# EFM32GG12B810F1024IL112 register map
File version: 3.0.0
CPU: CM4 r0p1, little endian, MPU, FPU, 3 interrupt priority bits
Registers are 32-bit, read-write, reset 0x0 unless marked. A register's access mark holds for its fields unless they carry their own. Offsets are from the block's base; [hi:lo] are bit positions; {n}, {i} and the like mark numbered series; 'fields as' and 'values as' point back to an identical list.

## CAN0
Base 0x40004000
Same registers: CAN1 0x40004400
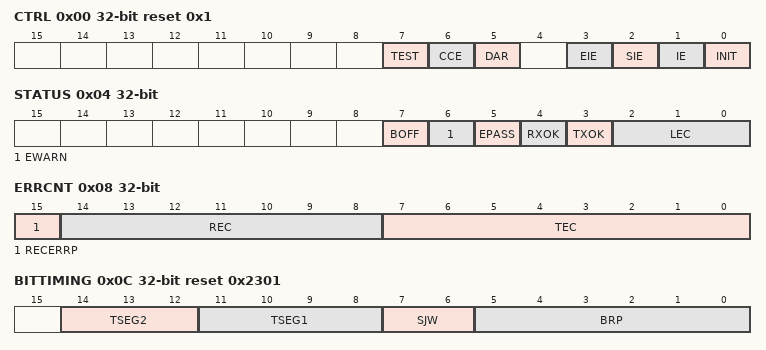
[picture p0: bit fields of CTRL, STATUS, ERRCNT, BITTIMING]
0x00 CTRL reset 0x1 — Control Register
  [7] TEST — Test Mode Enable Write
  [6] CCE — Configuration Change Enable
  [5] DAR — Disable Automatic Retransmission
  [3] EIE — Error Interrupt Enable
  [2] SIE — Status Change Interrupt Enable
  [1] IE — Module Interrupt Enable
  [0] INIT — Initialize
0x04 STATUS
  [7] BOFF ro — Bus Off Status
  [6] EWARN ro — Warning Status
  [5] EPASS ro — Error Passive
  [4] RXOK — Received a Message Successfully
  [3] TXOK — Transmitted a Message Successfully
  [2:0] LEC — Last Error Code
    0=NONE (No error occurred during last CAN bus event.); 1=STUFF (More than 5 equal bits in a sequence have occurred in a part of a received message where this is not allowed.); 2=FORM (A fixed format part of a received frame has the wrong format.); 3=ACK (The message this CAN Core transmitted was not acknowledged by another node.); 4=BIT1 (During the transmission of a message (with the exception of the arbitration field), the device wanted to send a recessive level (bit of logical value 1), but the monitored bus value was dominant.); 5=BIT0 (During the transmission of a message (or acknowledge bit, or active error flag, or overload flag), the device wanted to send a dominant level (data or identifier bit logical value 0), but the monitored Bus value was recessive. During Bus Off recovery this status is set each time a sequence of 11 recessive bits has been monitored. This enables the CPU to monitor the proceeding of the Bus Off recovery sequence (indicating the bus is not stuck at dominant or continuously disturbed).); 6=CRC (The CRC check sum was incorrect in the message received; the CRC received for an incoming message does not match with the calculated CRC for the received data.); 7=UNUSED (When the LEC shows the value '7', no CAN bus event was detected since the CPU wrote this value to the LEC.)
0x08 ERRCNT ro — Error Count Register
  [15] RECERRP — Receive Error Passive
  [14:8] REC — Receive Error Counter
  [7:0] TEC — Transmit Error Counter
0x0C BITTIMING reset 0x2301
  [14:12] TSEG2 — Time Segment After the Sample Point
  [11:8] TSEG1 — Time Segment Before the Sample Point
  [7:6] SJW — Synchronization Jump Width
  [5:0] BRP — Baud Rate Prescaler
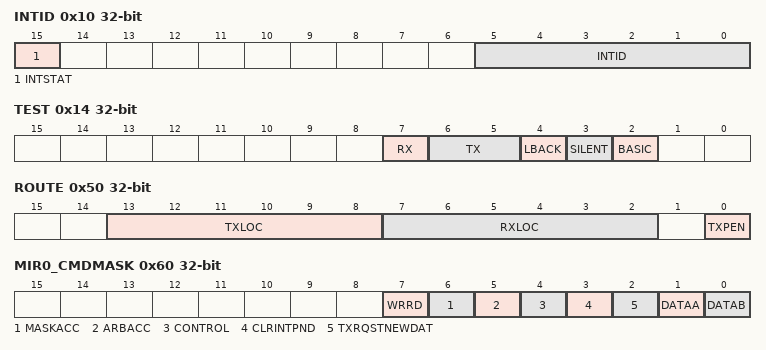
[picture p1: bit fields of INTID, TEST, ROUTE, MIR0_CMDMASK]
0x10 INTID ro — Interrupt Identification Register
  [15] INTSTAT — Status Interupt
  [5:0] INTID — Interrupt Identifier
0x14 TEST
  [7] RX ro — Monitors the Actual Value of CAN_RX Pin
  [6:5] TX — Control of CAN_TX Pin
    0=CORE (Reset value, CAN_TX is controlled by the CAN Core.); 1=SAMPT (Sample Point can be monitored at CAN_TX pin.); 2=LOW (CAN_TX pin drives a dominant bit (0) value.); 3=HIGH (CAN_TX pin drives a recessive bit (1) value.)
  [4] LBACK — Loopback Mode
  [3] SILENT — Silent Mode
  [2] BASIC — Basic Mode
0x18 BRPE — BRP Extension Register
  [3:0] BRPE — Baud Rate Prescaler Extension
0x1C TRANSREQ ro — Transmission Request Register
  [31:0] TXRQSTOUT — Transmission Request Bits (Of All Message Objects)
    0=FALSE (This Message Object is not waiting for transmission.); 1=TRUE (The transmission of this Message Object is requested and is not yet done.)
0x20 MESSAGEDATA ro — New Data Register
  [31:0] VALID — DATAVALID Bits (of All Message Objects)
0x28 MESSAGESTATE ro — Message Valid Register
  [31:0] VALID — Message Valid Bits (of All Message Objects)
0x2C CONFIG — Configuration Register
  [15] DBGHALT — Debug Halt
0x30 IF0IF ro — Message Object Interrupt Flag Register
  [31:0] MESSAGE — Message Object Interrupt Flag
0x34 IF0IFS wo — Message Object Interrupt Flag Set Register
  [31:0] MESSAGE — Set MESSAGE Interrupt Flag
0x38 IF0IFC wo — Message Object Interrupt Flag Clear Register
  [31:0] MESSAGE — Clear MESSAGE Interrupt Flag
0x3C IF0IEN reset 0xFFFFFFFF — Message Object Interrupt Enable Register
  [31:0] MESSAGE — MESSAGE Interrupt Enable
0x40 IF1IF ro — Status Interrupt Flag Register
  [0] STATUS — Status Interrupt Flag
0x44 IF1IFS wo — Message Object Interrupt Flag Set Register
  [0] STATUS — Set STATUS Interrupt Flag
0x48 IF1IFC wo — Message Object Interrupt Flag Clear Register
  [0] STATUS — Clear STATUS Interrupt Flag
0x4C IF1IEN reset 0x1 — Status Interrupt Enable Register
  [0] STATUS — STATUS Interrupt Enable
0x50 ROUTE — I/O Routing Register
  [13:8] TXLOC — TX Pin Location
    {v}=LOC{v} (Location {v}) (v=0..6)
  [7:2] RXLOC — RX Pin Location
    {v}=LOC{v} (Location {v}) (v=0..6)
  [0] TXPEN — TX Pin Enable
0x60 MIR0_CMDMASK — Interface Command Mask Register
  [7] WRRD — Write/Read RAM
  [6] MASKACC — Access Mask Bits
  [5] ARBACC — Access Arbitration Bits
  [4] CONTROL — Access Control Bits
  [3] CLRINTPND — Clear Interrupt Pending Bit
  [2] TXRQSTNEWDAT — Transmission Request Bit/ New Data Bit
  [1] DATAA — Access Data Bytes 0-3
  [0] DATAB — CC Channel Mode
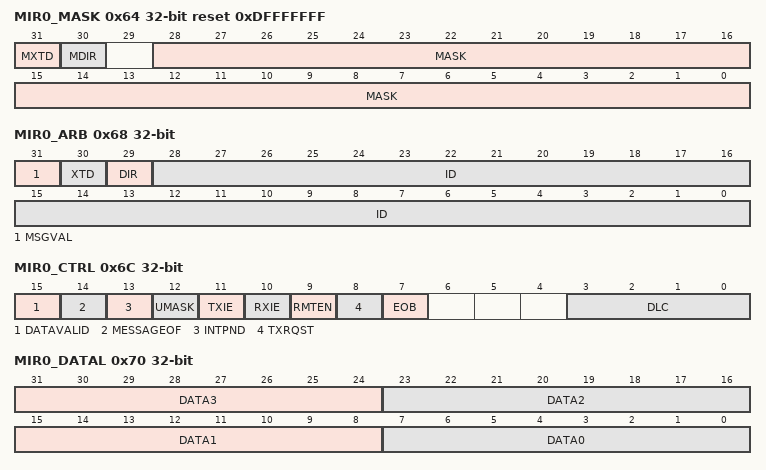
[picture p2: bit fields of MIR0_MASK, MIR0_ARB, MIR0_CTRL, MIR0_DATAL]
0x64 MIR0_MASK reset 0xDFFFFFFF — Interface Mask Register
  [31] MXTD — Mask Extended Identifier
  [30] MDIR — Mask Message Direction
  [28:0] MASK — Identifier Mask
0x68 MIR0_ARB — Interface Arbitration Register
  [31] MSGVAL — Message Valid
  [30] XTD — Extended Identifier
  [29] DIR — Message Direction
  [28:0] ID — Message Identifier
0x6C MIR0_CTRL — Interface Message Control Register
  [15] DATAVALID — New Data
  [14] MESSAGEOF — Message Lost (only Valid for Message Objects With Direction = Receive)
  [13] INTPND — Interrupt Pending
  [12] UMASK — Use Acceptance Mask
  [11] TXIE — Transmit Interrupt Enable
  [10] RXIE — Receive Interrupt Enable
  [9] RMTEN — Remote Enable
  [8] TXRQST — Transmit Request
  [7] EOB — End of Buffer
  [3:0] DLC — Data Length Code
0x70 MIR0_DATAL — Interface Data a Register
  [31:24] DATA3 — Fourth Byte of CAN Data Frame
  [23:16] DATA2 — Third Byte of CAN Data Frame
  [15:8] DATA1 — Second Byte of CAN Data Frame
  [7:0] DATA0 — First Byte of CAN Data Frame
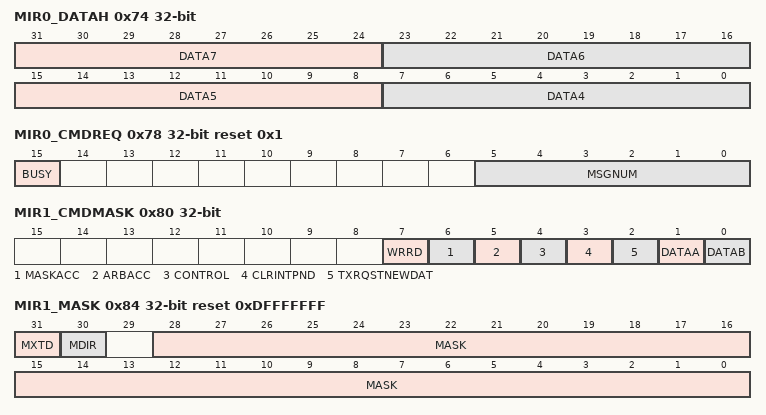
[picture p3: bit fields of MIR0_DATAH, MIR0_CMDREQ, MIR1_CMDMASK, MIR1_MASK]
0x74 MIR0_DATAH — Interface Data B Register
  [31:24] DATA7 — Eight Byte of CAN Data Frame
  [23:16] DATA6 — Seventh Byte of CAN Data Frame
  [15:8] DATA5 — Sixth Byte of CAN Data Frame
  [7:0] DATA4 — Fifth Byte of CAN Data Frame
0x78 MIR0_CMDREQ reset 0x1 — Interface Command Request Register
  [15] BUSY ro — Busy Flag
  [5:0] MSGNUM — Message Number
0x80 MIR1_CMDMASK — Interface Command Mask Register
  fields as MIR0_CMDMASK
0x84 MIR1_MASK reset 0xDFFFFFFF — Interface Mask Register
  fields as MIR0_MASK
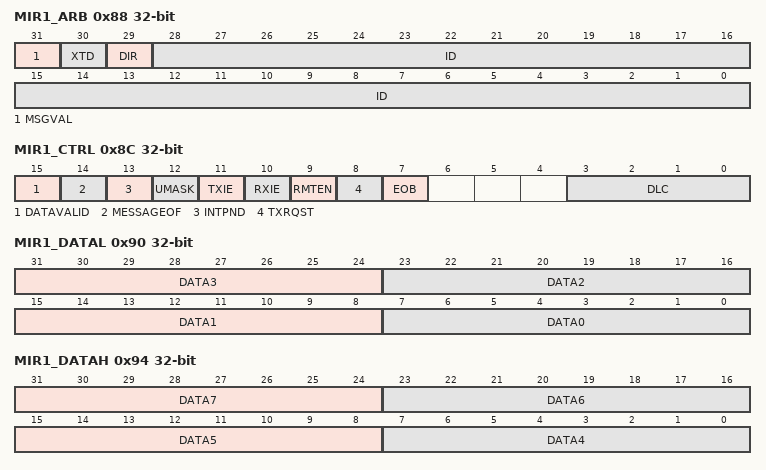
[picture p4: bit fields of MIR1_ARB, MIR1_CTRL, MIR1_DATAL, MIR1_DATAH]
0x88 MIR1_ARB — Interface Arbitration Register
  fields as MIR0_ARB
0x8C MIR1_CTRL — Interface Message Control Register
  fields as MIR0_CTRL
0x90 MIR1_DATAL — Interface Data a Register
  fields as MIR0_DATAL
0x94 MIR1_DATAH — Interface Data B Register
  fields as MIR0_DATAH
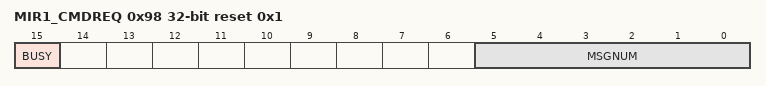
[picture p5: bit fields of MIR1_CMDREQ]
0x98 MIR1_CMDREQ reset 0x1 — Interface Command Request Register
  [15] BUSY ro — Busy Flag
  [5:0] MSGNUM — Message Number

## Notices in the file
# License
Copyright 2020 Silicon Laboratories Inc. www.silabs.com
SPDX-License-Identifier: Zlib
The licensor of this software is Silicon Laboratories Inc.
This software is provided 'as-is', without any express or implied
warranty. In no event will the authors be held liable for any damages
arising from the use of this software.
Permission is granted to anyone to use this software for any purpose,
including commercial applications, and to alter it and redistribute it
freely, subject to the following restrictions:
1. The origin of this software must not be misrepresented; you must not
claim that you wrote the original software. If you use this software
in a product, an acknowledgment in the product documentation would be
appreciated but is not required.
2. Altered source versions must be plainly marked as such, and must not be
misrepresented as being the original software.
3. This notice may not be removed or altered from any source distribution.
